VERSION ""

NS_ :

BS_:

BU_: XXX

BO_ 528 TRACK_0: 8 XXX
 SG_ LONG_DIST : 15|16@0- (1,0) [0|65535] "" XXX
 SG_ COUNTER : 7|8@0+ (1,0) [0|255] "" XXX

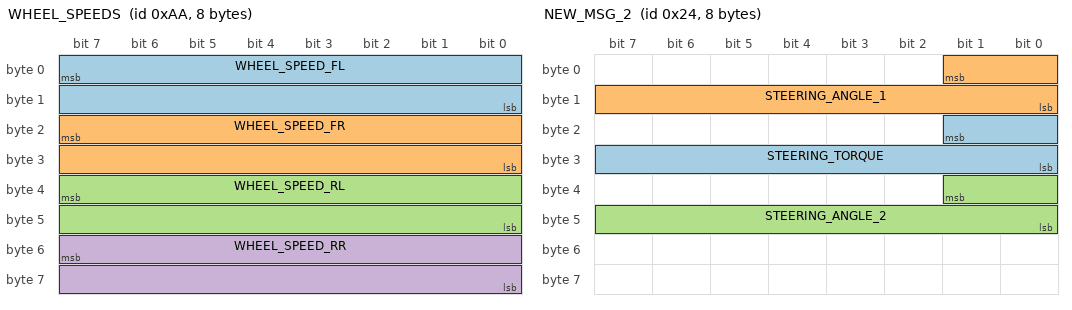
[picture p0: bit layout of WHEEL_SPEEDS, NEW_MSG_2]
BO_ 170 WHEEL_SPEEDS: 8 XXX
 SG_ WHEEL_SPEED_FL : 7|16@0+ (1,-6767) [0|65535] "" XXX
 SG_ WHEEL_SPEED_FR : 23|16@0+ (1,-6767) [0|65535] "" XXX
 SG_ WHEEL_SPEED_RL : 39|16@0+ (1,-6767) [0|65535] "" XXX
 SG_ WHEEL_SPEED_RR : 55|16@0+ (1,-6767) [0|65535] "" XXX

BO_ 552 NEW_MSG_1: 8 XXX

BO_ 166 BRAKE: 8 XXX
 SG_ BRAKE_AMOUNT : 7|8@0+ (1,0) [0|255] "" XXX
 SG_ BRAKE_PEDAL : 23|8@0+ (1,0) [0|255] "" XXX

BO_ 36 NEW_MSG_2: 8 XXX
 SG_ STEERING_TORQUE : 17|10@0+ (1,-512) [0|65535] "" XXX
 SG_ STEERING_ANGLE_1 : 1|10@0+ (1,-512) [0|65535] "" XXX
 SG_ STEERING_ANGLE_2 : 33|10@0+ (1,-512) [0|65535] "" XXX

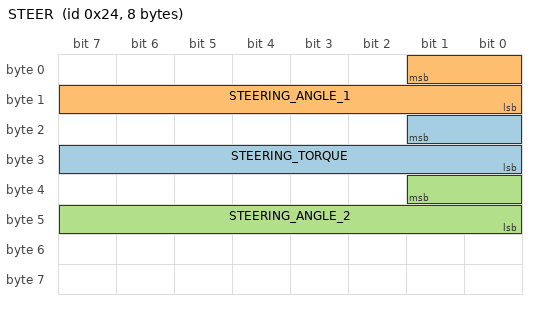
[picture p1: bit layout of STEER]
BO_ 36 STEER: 8 XXX
 SG_ STEERING_TORQUE : 17|10@0+ (1,-512) [0|65535] "" XXX
 SG_ STEERING_ANGLE_1 : 1|10@0+ (1,-512) [0|65535] "" XXX
 SG_ STEERING_ANGLE_2 : 33|10@0+ (1,-512) [0|65535] "" XXX
